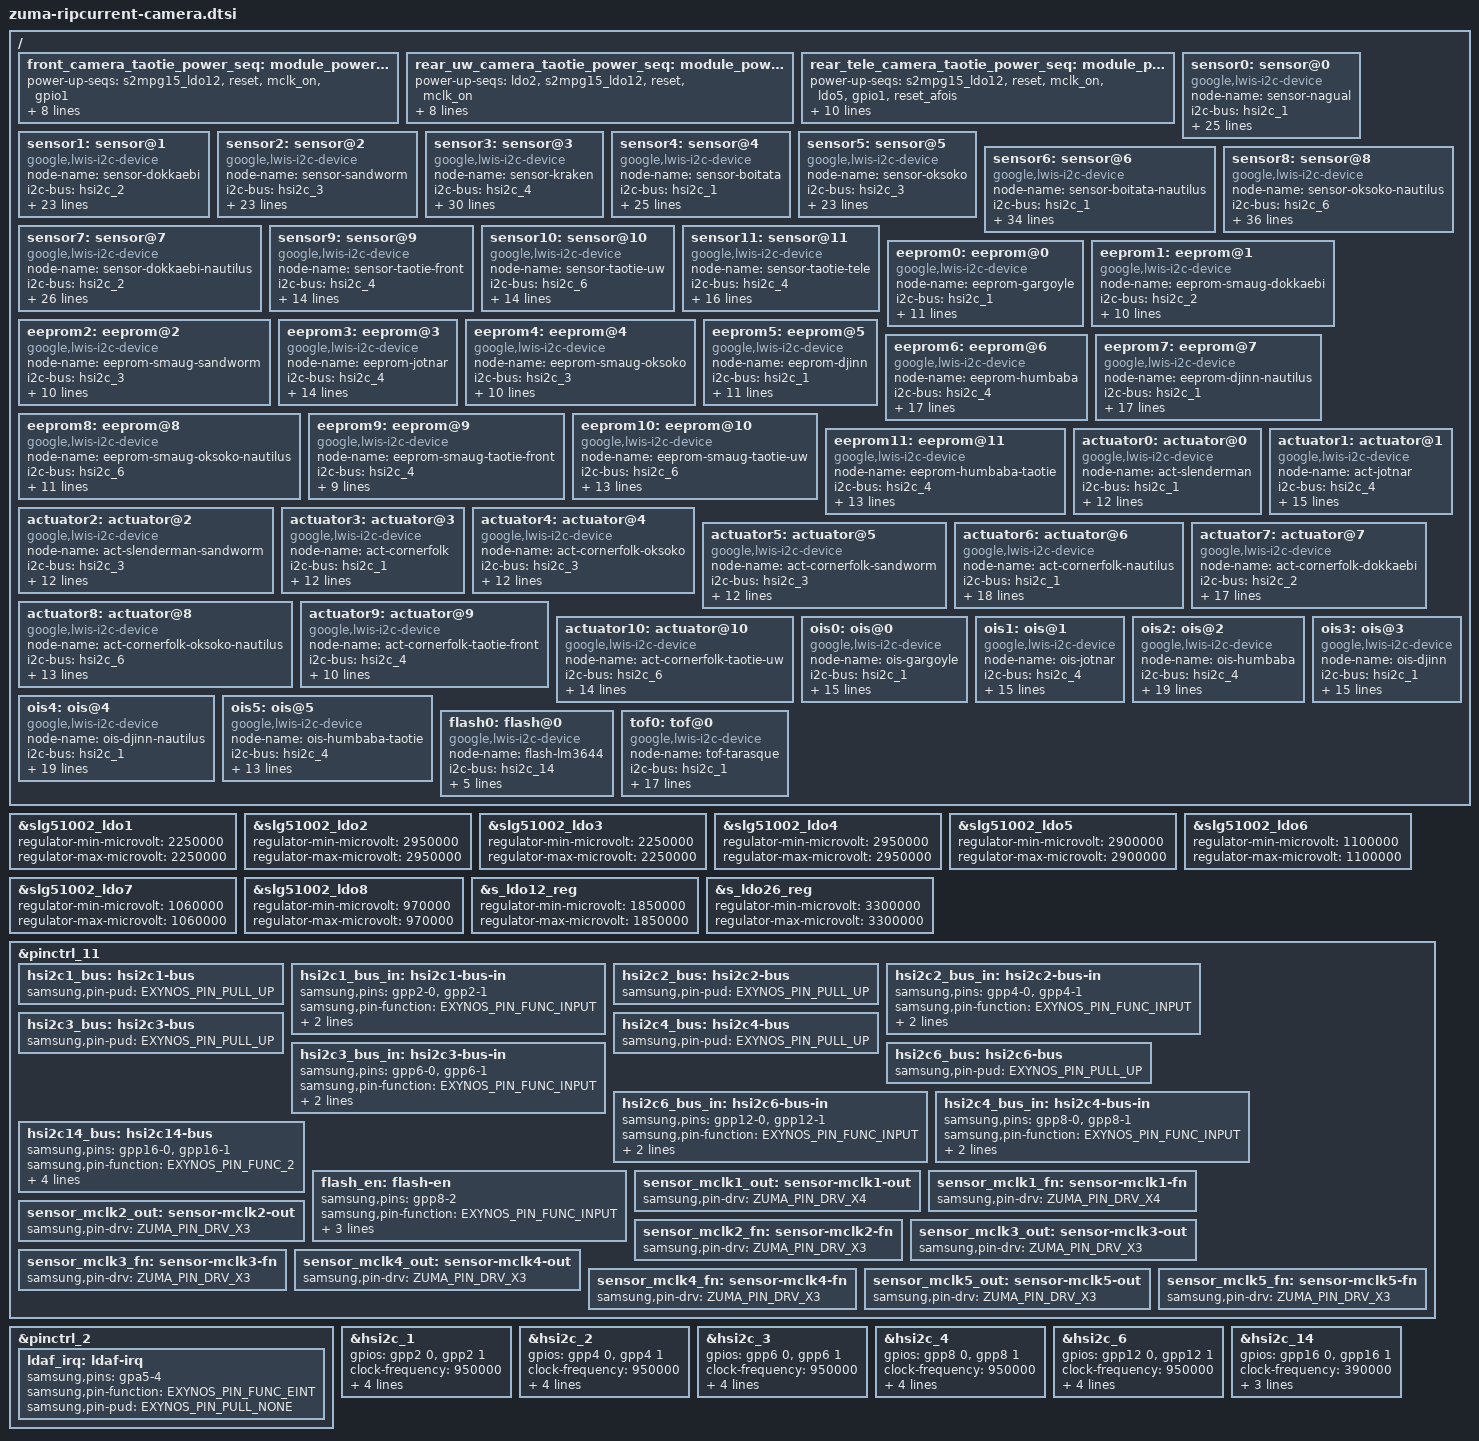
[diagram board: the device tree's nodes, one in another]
// SPDX-License-Identifier: GPL-2.0-only
/*
 * zuma camera lwis device tree for ripcurrent
 *
 * Copyright 2022 Google LLC.
 *
 */

#include <dt-bindings/clock/zuma.h>
#include <dt-bindings/gpio/gpio.h>
#include <arm64/exynos/exynos-pinctrl.h>
#include <dt-bindings/lwis/platform/zuma/tof.h>

&slg51002_ldo1 {
	regulator-min-microvolt = <2250000>;
	regulator-max-microvolt = <2250000>;
};

&slg51002_ldo2 {
	regulator-min-microvolt = <2950000>;
	regulator-max-microvolt = <2950000>;
};

&slg51002_ldo3 {
	regulator-min-microvolt = <2250000>;
	regulator-max-microvolt = <2250000>;
};

&slg51002_ldo4 {
	regulator-min-microvolt = <2950000>;
	regulator-max-microvolt = <2950000>;
};

&slg51002_ldo5 {
	regulator-min-microvolt = <2900000>;
	regulator-max-microvolt = <2900000>;
};

&slg51002_ldo6 {
	regulator-min-microvolt = <1100000>;
	regulator-max-microvolt = <1100000>;
};

&slg51002_ldo7 {
	regulator-min-microvolt = <1060000>;
	regulator-max-microvolt = <1060000>;
};

&slg51002_ldo8 {
	regulator-min-microvolt = <970000>;
	regulator-max-microvolt = <970000>;
};

&s_ldo12_reg {
	regulator-min-microvolt = <1850000>;
	regulator-max-microvolt = <1850000>;
};

&s_ldo26_reg {
	regulator-min-microvolt = <3300000>;
	regulator-max-microvolt = <3300000>;
};

&pinctrl_11 {
	hsi2c1_bus: hsi2c1-bus {
		samsung,pin-pud = <EXYNOS_PIN_PULL_UP>;
	};

	hsi2c1_bus_in: hsi2c1-bus-in {
		samsung,pins = "gpp2-0", "gpp2-1";
		samsung,pin-function = <EXYNOS_PIN_FUNC_INPUT>;
		samsung,pin-pud = <EXYNOS_PIN_PULL_NONE>;
		samsung,pin-drv = <ZUMA_PIN_DRV_X1>;
	};

	hsi2c2_bus: hsi2c2-bus {
		samsung,pin-pud = <EXYNOS_PIN_PULL_UP>;
	};

	hsi2c2_bus_in: hsi2c2-bus-in {
		samsung,pins = "gpp4-0", "gpp4-1";
		samsung,pin-function = <EXYNOS_PIN_FUNC_INPUT>;
		samsung,pin-pud = <EXYNOS_PIN_PULL_NONE>;
		samsung,pin-drv = <ZUMA_PIN_DRV_X1>;
	};

	hsi2c3_bus: hsi2c3-bus {
		samsung,pin-pud = <EXYNOS_PIN_PULL_UP>;
	};

	hsi2c3_bus_in: hsi2c3-bus-in {
		samsung,pins = "gpp6-0", "gpp6-1";
		samsung,pin-function = <EXYNOS_PIN_FUNC_INPUT>;
		samsung,pin-pud = <EXYNOS_PIN_PULL_NONE>;
		samsung,pin-drv = <ZUMA_PIN_DRV_X1>;
	};

	hsi2c4_bus: hsi2c4-bus {
		samsung,pin-pud = <EXYNOS_PIN_PULL_UP>;
	};

	hsi2c6_bus: hsi2c6-bus {
		samsung,pin-pud = <EXYNOS_PIN_PULL_UP>;
	};

	hsi2c6_bus_in: hsi2c6-bus-in {
		samsung,pins = "gpp12-0", "gpp12-1";
		samsung,pin-function = <EXYNOS_PIN_FUNC_INPUT>;
		samsung,pin-pud = <EXYNOS_PIN_PULL_NONE>;
		samsung,pin-drv = <ZUMA_PIN_DRV_X1>;
	};

	hsi2c4_bus_in: hsi2c4-bus-in {
		samsung,pins = "gpp8-0", "gpp8-1";
		samsung,pin-function = <EXYNOS_PIN_FUNC_INPUT>;
		samsung,pin-pud = <EXYNOS_PIN_PULL_NONE>;
		samsung,pin-drv = <ZUMA_PIN_DRV_X1>;
	};

	hsi2c14_bus: hsi2c14-bus {
		samsung,pins = "gpp16-0", "gpp16-1";
		samsung,pin-function = <EXYNOS_PIN_FUNC_2>;
		samsung,pin-pud = <EXYNOS_PIN_PULL_NONE>;
		samsung,pin-drv = <ZUMA_PIN_DRV_X1>;
		samsung,pin-con-pdn = <EXYNOS_PIN_PDN_PREV>;
		samsung,pin-pud-pdn = <EXYNOS_PIN_PULL_NONE>;
	};

	/* GPP8[2] Flashlight Enable */
	flash_en: flash-en {
		samsung,pins = "gpp8-2";
		samsung,pin-function = <EXYNOS_PIN_FUNC_INPUT>;
		samsung,pin-pud = <EXYNOS_PIN_PULL_NONE>;
		samsung,pin-con-pdn = <EXYNOS_PIN_PDN_PREV>;
		samsung,pin-pud-pdn = <EXYNOS_PIN_PULL_NONE>;
	};

	sensor_mclk1_out: sensor-mclk1-out {
		samsung,pin-drv = <ZUMA_PIN_DRV_X4>;
	};
	sensor_mclk1_fn: sensor-mclk1-fn {
		samsung,pin-drv = <ZUMA_PIN_DRV_X4>;
	};
	sensor_mclk2_out: sensor-mclk2-out {
		samsung,pin-drv = <ZUMA_PIN_DRV_X3>;
	};
	sensor_mclk2_fn: sensor-mclk2-fn {
		samsung,pin-drv = <ZUMA_PIN_DRV_X3>;
	};
	sensor_mclk3_out: sensor-mclk3-out {
		samsung,pin-drv = <ZUMA_PIN_DRV_X3>;
	};
	sensor_mclk3_fn: sensor-mclk3-fn {
		samsung,pin-drv = <ZUMA_PIN_DRV_X3>;
	};
	sensor_mclk4_out: sensor-mclk4-out {
		samsung,pin-drv = <ZUMA_PIN_DRV_X3>;
	};
	sensor_mclk4_fn: sensor-mclk4-fn {
		samsung,pin-drv = <ZUMA_PIN_DRV_X3>;
	};
	sensor_mclk5_out: sensor-mclk5-out {
		samsung,pin-drv = <ZUMA_PIN_DRV_X3>;
	};
	sensor_mclk5_fn: sensor-mclk5-fn {
		samsung,pin-drv = <ZUMA_PIN_DRV_X3>;
	};
};

&pinctrl_2 {
	ldaf_irq: ldaf-irq {
		samsung,pins = "gpa5-4"; /* XEINT_4 */
		samsung,pin-function = <EXYNOS_PIN_FUNC_EINT>;
		samsung,pin-pud = <EXYNOS_PIN_PULL_NONE>;
	};
};

&hsi2c_1 {
	#address-cells = <1>;
	#size-cells = <0>;
	gpios = <&gpp2 0 GPIO_ACTIVE_HIGH &gpp2 1 GPIO_ACTIVE_HIGH>;
	status = "okay";
	clock-frequency = <950000>;
	samsung,reset-before-trans;

	pinctrl-names = "default","on_i2c","off_i2c";
	pinctrl-0 = <&hsi2c1_bus_in>;
	pinctrl-1 = <&hsi2c1_bus>;
	pinctrl-2 = <&hsi2c1_bus_in>;
};

&hsi2c_2 {
	#address-cells = <1>;
	#size-cells = <0>;
	gpios = <&gpp4 0 GPIO_ACTIVE_HIGH &gpp4 1 GPIO_ACTIVE_HIGH>;
	status = "okay";
	clock-frequency = <950000>;
	samsung,reset-before-trans;

	pinctrl-names = "default","on_i2c","off_i2c";
	pinctrl-0 = <&hsi2c2_bus_in>;
	pinctrl-1 = <&hsi2c2_bus>;
	pinctrl-2 = <&hsi2c2_bus_in>;
};

&hsi2c_3 {
	#address-cells = <1>;
	#size-cells = <0>;
	gpios = <&gpp6 0 GPIO_ACTIVE_HIGH &gpp6 1 GPIO_ACTIVE_HIGH>;
	status = "okay";
	clock-frequency = <950000>;
	samsung,reset-before-trans;

	pinctrl-names = "default","on_i2c","off_i2c";
	pinctrl-0 = <&hsi2c3_bus_in>;
	pinctrl-1 = <&hsi2c3_bus>;
	pinctrl-2 = <&hsi2c3_bus_in>;
};

&hsi2c_4 {
	#address-cells = <1>;
	#size-cells = <0>;
	gpios = <&gpp8 0 GPIO_ACTIVE_HIGH &gpp8 1 GPIO_ACTIVE_HIGH>;
	status = "okay";
	clock-frequency = <950000>;
	samsung,reset-before-trans;

	pinctrl-names = "default","on_i2c","off_i2c";
	pinctrl-0 = <&hsi2c4_bus_in>;
	pinctrl-1 = <&hsi2c4_bus>;
	pinctrl-2 = <&hsi2c4_bus_in>;
};

&hsi2c_6 {
	#address-cells = <1>;
	#size-cells = <0>;
	gpios = <&gpp12 0 GPIO_ACTIVE_HIGH &gpp12 1 GPIO_ACTIVE_HIGH>;
	status = "okay";
	clock-frequency = <950000>;
	samsung,reset-before-trans;

	pinctrl-names = "default","on_i2c","off_i2c";
	pinctrl-0 = <&hsi2c6_bus_in>;
	pinctrl-1 = <&hsi2c6_bus>;
	pinctrl-2 = <&hsi2c6_bus_in>;
};

&hsi2c_14 {
	#address-cells = <1>;
	#size-cells = <0>;
	gpios = <&gpp16 0 GPIO_ACTIVE_HIGH &gpp16 1 GPIO_ACTIVE_HIGH>;
	status = "okay";
	clock-frequency = <390000>;

	pinctrl-names = "default","on_i2c","off_i2c";
	pinctrl-0 = <&hsi2c14_bus &flash_en>;
	pinctrl-1 = <&hsi2c14_bus>;
	pinctrl-2 = <&hsi2c14_bus>;
};
/ {
	fragment@lwiscamera {
		target-path = "/";
		__overlay__ {
			/* Power sequence for FRONT CAMERA TAOTIE combo */
			front_camera_taotie_power_seq: module_power_seq@0 {
				/* Power supplies will be defined on each module. */
				/* Power up sequence */
				power-up-seqs =
					/* Sensor power seq */
					/* VDIG(EN_BUCK_CAM) already up from PMIC */
					"s2mpg15_ldo12",
					"reset",
					"mclk_on",
					/* Actuator power seq */
					"gpio1";
				power-up-seq-types =
					"regulator",
					"gpio",
					"pinctrl",
					"regulator";
				power-up-seq-delays-us =
					<1000
					 0
					 /* >40k cycles (50k) on 24.57MHz clock (24MHz) */
					 /* 50k / 24MHz = around 2ms */
					 /* +1ms for additional delay */
					 3000
					 0>;

				/* Power down sequence */
				power-down-seqs =
					"gpio1",
					"mclk_off",
					"reset",
					"s2mpg15_ldo12";
				power-down-seq-types =
					"regulator",
					"pinctrl",
					"gpio",
					"regulator";
				power-down-seq-delays-us =
					<1000
					 0
					 0
					 0>;
			};

			/* Power sequence for REAR ULTRA WIDE TAOTIE combo */
			rear_uw_camera_taotie_power_seq: module_power_seq@1 {
				/* Power supplies will be defined on each module. */
				/* Power up sequence */
				power-up-seqs =
					/* Sensor power seq */
					/* VDIG,VIO(EN_BUCK_CAM) already up from PMIC */
					"ldo2",
					/* Actuator also up by i2c power pin*/
					"s2mpg15_ldo12",
					"reset",
					"mclk_on";

				power-up-seq-types =
					"regulator",
					"regulator",
					"gpio",
					"pinctrl";
				power-up-seq-delays-us =
					<1000
					 0
					 0
					 /* >40k cycles (50k) on 24.57MHz clock (24MHz) */
					 /* 50k / 24MHz = around 2ms */
					 /* +1ms for additional delay */
					 3000>;

				/* Power down sequence */
				power-down-seqs =
					"mclk_off",
					"reset",
					"s2mpg15_ldo12",
					"ldo2";
				power-down-seq-types =
					"pinctrl",
					"gpio",
					"regulator",
					"regulator";
				power-down-seq-delays-us =
					<0
					 1000
					 0
					 0>;
			};

			/* Power sequence for REAR Folded Tele Camera TAOTIE combo */
			rear_tele_camera_taotie_power_seq: module_power_seq@2 {
				/* Power supplies will be defined on each module. */
				/* Power up sequence */
				power-up-seqs =
					/* Sensor power seq */
					/* VDIG(EN_BUCK_CAM) already up from PMIC */
					"s2mpg15_ldo12",
					"reset",
					"mclk_on",
					/* AFOIS power seq */
					/* VDDIO already up by i2c power */
					"ldo5",
					"gpio1",
					"reset_afois";
				power-up-seq-types =
					"regulator",
					"gpio",
					"pinctrl",
					"regulator",
					"regulator",
					"gpio";
				power-up-seq-delays-us =
					<1000
					 0
					 /* >40k cycles (50k) on 24.57MHz clock (24MHz) */
					 /* 50k / 24MHz = around 2ms */
					 /* +1ms for additional delay */
					 3000
					 1000
					 1000
					 0>;

				/* Power down sequence */
				power-down-seqs =
					"reset_afois",
					"gpio1",
					"ldo5",
					"mclk_off",
					"reset",
					"s2mpg15_ldo12";
				power-down-seq-types =
					"gpio",
					"regulator",
					"regulator",
					"pinctrl",
					"gpio",
					"regulator";
				power-down-seq-delays-us =
					<1000
					 1000
					 1000
					 1000
					 0
					 0>;
			};

			/* REAR CAMERA NAGUAL */
			sensor0: sensor@0 {
				compatible = "google,lwis-i2c-device";

				/* Device node name */
				node-name = "sensor-nagual";

				/* I2C */
				i2c-bus = <&hsi2c_1>;
				i2c-addr = <0x3D>;

				/* Registers */
				reg-addr-bitwidth = <16>;
				reg-value-bitwidth = <16>;

				/* GPIOs */
				/* RCAM_RST_L GPP2[2] */
				reset-gpios = <&gpp2 2 GPIO_ACTIVE_HIGH>;

				/* Power supplies */
				s2mpg15_ldo12-supply = <&s_ldo12_reg>;
				ldo1-supply = <&slg51002_ldo1>;
				ldo8-supply = <&slg51002_ldo8>;
				gpio3-supply = <&slg51002_gpio3>;

				clocks =
					<&clock CIS_CLK3>,
					<&clock GATE_DFTMUX_CMU_CIS_CLK3>;
				clock-names =
					"CIS_CLK3",
					"GATE_DFTMUX_CMU_CIS_CLK3";
				clock-rates =
					<26000000>,
					<0>;

				/* MCLK Control */
				pinctrl-names = "mclk_on", "mclk_off";
				pinctrl-0 = <&sensor_mclk4_fn>;
				pinctrl-1 = <&sensor_mclk4_out>;

				/* Power up sequence */
				power-up-seqs =
					"s2mpg15_ldo12",
					"gpio3",
					"ldo8",
					"ldo1",
					"reset",
					"mclk_on";
				power-up-seq-types =
					"regulator",
					"regulator",
					"regulator",
					"regulator",
					"gpio",
					"pinctrl";
				power-up-seq-delays-us =
					<1000
					 0
					 0
					 2000
					 1000
					 9000>;

				/* Power down sequence */
				power-down-seqs =
					"mclk_off",
					"reset",
					"ldo1",
					"ldo8",
					"gpio3",
					"s2mpg15_ldo12";
				power-down-seq-types =
					"pinctrl",
					"gpio",
					"regulator",
					"regulator",
					"regulator",
					"regulator";
				power-down-seq-delays-us =
					<1000
					 1000
					 0
					 0
					 6000
					 0>;

				/* Thread priority */
				transaction-thread-priority = <99>;
			};

			/* FRONT CAMERA DOKKAEBI */
			sensor1: sensor@1 {
				compatible = "google,lwis-i2c-device";

				/* Device node name */
				node-name = "sensor-dokkaebi";

				/* I2C */
				i2c-bus = <&hsi2c_2>;
				i2c-addr = <0x10>;

				/* Registers */
				reg-addr-bitwidth = <16>;
				reg-value-bitwidth = <16>;

				/* GPIOs */
				reset-gpios = <&gpp4 2 GPIO_ACTIVE_HIGH>;

				/* Power supplies */
				s2mpg15_ldo12-supply = <&s_ldo12_reg>;
				ldo8-supply = <&slg51002_ldo8>;
				gpio4-supply = <&slg51002_gpio4>;

				clocks =
					<&clock CIS_CLK1>,
					<&clock GATE_DFTMUX_CMU_CIS_CLK1>;
				clock-names =
					"CIS_CLK1",
					"GATE_DFTMUX_CMU_CIS_CLK1";
				clock-rates =
					<24000000>,
					<0>;

				/* MCLK Control */
				pinctrl-names = "mclk_on", "mclk_off";
				pinctrl-0 = <&sensor_mclk2_fn>;
				pinctrl-1 = <&sensor_mclk2_out>;

				/* Power up sequence */
				power-up-seqs =
					"s2mpg15_ldo12",
					"ldo8",
					"gpio4",
					"mclk_on",
					"reset";
				power-up-seq-types =
					"regulator",
					"regulator",
					"regulator",
					"pinctrl",
					"gpio";
				power-up-seq-delays-us =
					<0
					 0
					 1000
					 1000
					 8000>;

				/* Power down sequence */
				power-down-seqs =
					"reset",
					"mclk_off",
					"gpio4",
					"ldo8",
					"s2mpg15_ldo12";
				power-down-seq-types =
					"gpio",
					"pinctrl",
					"regulator",
					"regulator",
					"regulator";
				power-down-seq-delays-us =
					<0
					 1000
					 0
					 0
					 1000>;

				/* Thread priority */
				transaction-thread-priority = <99>;
			};

			/* REAR ULTRA WIDE CAMERA SANDWORM */
			sensor2: sensor@2 {
				compatible = "google,lwis-i2c-device";

				/* Device node name */
				node-name = "sensor-sandworm";

				/* I2C */
				i2c-bus = <&hsi2c_3>;
				i2c-addr = <0x1A>;

				/* Registers */
				reg-addr-bitwidth = <16>;
				reg-value-bitwidth = <8>;

				/* GPIOs */
				reset-gpios = <&gpp6 3 GPIO_ACTIVE_HIGH>;

				/* Power supplies */
				s2mpg15_ldo12-supply = <&s_ldo12_reg>;
				ldo2-supply = <&slg51002_ldo2>;
				ldo6-supply = <&slg51002_ldo6>;

				clocks =
					<&clock CIS_CLK0>,
					<&clock GATE_DFTMUX_CMU_CIS_CLK0>;
				clock-names =
					"CIS_CLK0",
					"GATE_DFTMUX_CMU_CIS_CLK0";
				clock-rates =
					<24000000>,
					<0>;

				/* MCLK Control */
				pinctrl-names = "mclk_on", "mclk_off";
				pinctrl-0 = <&sensor_mclk1_fn>;
				pinctrl-1 = <&sensor_mclk1_out>;

				/* Power up sequence */
				power-up-seqs =
					"s2mpg15_ldo12",
					"ldo6",
					"ldo2",
					"mclk_on",
					"reset";
				power-up-seq-types =
					"regulator",
					"regulator",
					"regulator",
					"pinctrl",
					"gpio";
				power-up-seq-delays-us =
					<0
					 0
					 1000
					 1000
					 10000>;

				/* Power down sequence */
				power-down-seqs =
					"reset",
					"mclk_off",
					"ldo2",
					"ldo6",
					"s2mpg15_ldo12";
				power-down-seq-types =
					"gpio",
					"pinctrl",
					"regulator",
					"regulator",
					"regulator";
				power-down-seq-delays-us =
					<1000
					 1000
					 0
					 0
					 1000>;

				/* Thread priority */
				transaction-thread-priority = <99>;
			};

			/* REAR Folded Tele Camera KRAKEN */
			sensor3: sensor@3 {
				compatible = "google,lwis-i2c-device";

				/* Device node name */
				node-name = "sensor-kraken";

				/* I2C */
				i2c-bus = <&hsi2c_4>;
				i2c-addr = <0x2D>;

				/* Registers */
				reg-addr-bitwidth = <16>;
				reg-value-bitwidth = <16>;

				/* GPIOs */
				/* RTCAM_RST_L GPP6[2] */
				reset-gpios = <&gpp6 2 GPIO_ACTIVE_HIGH>;

				/* Power supplies */
				s2mpg15_ldo12-supply = <&s_ldo12_reg>;
				ldo3-supply = <&slg51002_ldo3>;
				ldo5-supply = <&slg51002_ldo5>;
				ldo7-supply = <&slg51002_ldo7>;
				gpio2-supply = <&slg51002_gpio2>;
				gpio4-supply = <&slg51002_gpio4>;

				clocks =
					<&clock CIS_CLK2>,
					<&clock GATE_DFTMUX_CMU_CIS_CLK2>;
				clock-names =
					"CIS_CLK2",
					"GATE_DFTMUX_CMU_CIS_CLK2";
				clock-rates =
					<24000000>,
					<0>;

				/* MCLK Control */
				pinctrl-names = "mclk_on", "mclk_off";
				pinctrl-0 = <&sensor_mclk3_fn>;
				pinctrl-1 = <&sensor_mclk3_out>;

				/* Power up sequence */
				power-up-seqs =
					"s2mpg15_ldo12",
					"ldo7",
					"ldo3",
					"ldo5",
					"gpio4",
					"mclk_on",
					"reset";
				power-up-seq-types =
					"regulator",
					"regulator",
					"regulator",
					"regulator",
					"regulator",
					"pinctrl",
					"gpio";
				power-up-seq-delays-us =
					<300
					 0
					 0
					 500
					 500
					 1000
					 10000>;

				/* Power down sequence */
				power-down-seqs =
					"reset",
					"mclk_off",
					"gpio4",
					"ldo5",
					"ldo7",
					"s2mpg15_ldo12",
					"ldo3";
				power-down-seq-types =
					"gpio",
					"pinctrl",
					"regulator",
					"regulator",
					"regulator",
					"regulator",
					"regulator";
				power-down-seq-delays-us =
					<0
					 0
					 1000
					 0
					 0
					 0
					 0>;

				/* Thread priority */
				transaction-thread-priority = <99>;

				i2c-lock-group-id = <3>;
			};

			/* REAR CAMERA BOITATA */
			sensor4: sensor@4 {
				compatible = "google,lwis-i2c-device";

				/* Device node name */
				node-name = "sensor-boitata";

				/* I2C */
				i2c-bus = <&hsi2c_1>;
				i2c-addr = <0x3D>;

				/* Registers */
				reg-addr-bitwidth = <16>;
				reg-value-bitwidth = <16>;

				/* GPIOs */
				/* RCAM_RST_L GPP2[2] */
				reset-gpios = <&gpp2 2 GPIO_ACTIVE_HIGH>;

				/* Power supplies */
				s2mpg15_ldo12-supply = <&s_ldo12_reg>;
				ldo1-supply = <&slg51002_ldo1>;
				ldo8-supply = <&slg51002_ldo8>;
				gpio3-supply = <&slg51002_gpio3>;

				clocks =
					<&clock CIS_CLK3>,
					<&clock GATE_DFTMUX_CMU_CIS_CLK3>;
				clock-names =
					"CIS_CLK3",
					"GATE_DFTMUX_CMU_CIS_CLK3";
				clock-rates =
					<26000000>,
					<0>;

				/* MCLK Control */
				pinctrl-names = "mclk_on", "mclk_off";
				pinctrl-0 = <&sensor_mclk4_fn>;
				pinctrl-1 = <&sensor_mclk4_out>;

				/* Power up sequence */
				power-up-seqs =
					"s2mpg15_ldo12",
					"gpio3",
					"ldo8",
					"ldo1",
					"reset",
					"mclk_on";
				power-up-seq-types =
					"regulator",
					"regulator",
					"regulator",
					"regulator",
					"gpio",
					"pinctrl";
				power-up-seq-delays-us =
					<1000
					 0
					 0
					 2000
					 1000
					 9000>;

				/* Power down sequence */
				power-down-seqs =
					"mclk_off",
					"reset",
					"ldo1",
					"ldo8",
					"gpio3",
					"s2mpg15_ldo12";
				power-down-seq-types =
					"pinctrl",
					"gpio",
					"regulator",
					"regulator",
					"regulator",
					"regulator";
				power-down-seq-delays-us =
					<1000
					 1000
					 0
					 0
					 6000
					 0>;

				/* Thread priority */
				transaction-thread-priority = <99>;
			};

			/* REAR ULTRA WIDE CAMERA OKSOKO */
			sensor5: sensor@5 {
				compatible = "google,lwis-i2c-device";

				/* Device node name */
				node-name = "sensor-oksoko";

				/* I2C */
				i2c-bus = <&hsi2c_3>;
				i2c-addr = <0x1A>;

				/* Registers */
				reg-addr-bitwidth = <16>;
				reg-value-bitwidth = <8>;

				/* GPIOs */
				reset-gpios = <&gpp6 3 GPIO_ACTIVE_HIGH>;

				/* Power supplies */
				s2mpg15_ldo12-supply = <&s_ldo12_reg>;
				ldo2-supply = <&slg51002_ldo2>;
				ldo6-supply = <&slg51002_ldo6>;

				clocks =
					<&clock CIS_CLK0>,
					<&clock GATE_DFTMUX_CMU_CIS_CLK0>;
				clock-names =
					"CIS_CLK0",
					"GATE_DFTMUX_CMU_CIS_CLK0";
				clock-rates =
					<24000000>,
					<0>;

				/* MCLK Control */
				pinctrl-names = "mclk_on", "mclk_off";
				pinctrl-0 = <&sensor_mclk1_fn>;
				pinctrl-1 = <&sensor_mclk1_out>;

				/* Power up sequence */
				power-up-seqs =
					"s2mpg15_ldo12",
					"ldo6",
					"ldo2",
					"mclk_on",
					"reset";
				power-up-seq-types =
					"regulator",
					"regulator",
					"regulator",
					"pinctrl",
					"gpio";
				power-up-seq-delays-us =
					<0
					 0
					 1000
					 1000
					 10000>;

				/* Power down sequence */
				power-down-seqs =
					"reset",
					"mclk_off",
					"ldo2",
					"ldo6",
					"s2mpg15_ldo12";
				power-down-seq-types =
					"gpio",
					"pinctrl",
					"regulator",
					"regulator",
					"regulator";
				power-down-seq-delays-us =
					<1000
					 1000
					 0
					 0
					 1000>;

				/* Thread priority */
				transaction-thread-priority = <99>;
			};

			/* REAR CAMERA BOITATA Nautilus */
			sensor6: sensor@6 {
				compatible = "google,lwis-i2c-device";

				/* Device node name */
				node-name = "sensor-boitata-nautilus";

				/* I2C */
				i2c-bus = <&hsi2c_1>;
				i2c-addr = <0x3D>;

				/* Registers */
				reg-addr-bitwidth = <16>;
				reg-value-bitwidth = <16>;
				/* CAMS_LVBUCK_EN for ldo8 */
				enable-gpios = <&s2mpg15_gpio 2 GPIO_ACTIVE_HIGH>;

				/* GPIOs */
				/* RCAM_RST_L GPP2[2] */
				reset-gpios = <&gpp2 2 GPIO_ACTIVE_HIGH>;

				/* Power supplies */
				s2mpg15_ldo26-supply = <&s_ldo26_reg>;
				s2mpg15_ldo12-supply = <&s_ldo12_reg>;
				ldo1-supply = <&slg51002_ldo1>;
				ldo8-supply = <&slg51002_ldo8>;
				ldo4-supply = <&slg51002_ldo4>;
				gpio2-supply = <&slg51002_gpio2>;

				clocks =
					<&clock CIS_CLK3>,
					<&clock GATE_DFTMUX_CMU_CIS_CLK3>;
				clock-names =
					"CIS_CLK3",
					"GATE_DFTMUX_CMU_CIS_CLK3";
				clock-rates =
					<26000000>,
					<0>;

				/* MCLK Control */
				pinctrl-names = "mclk_on", "mclk_off";
				pinctrl-0 = <&sensor_mclk4_fn>;
				pinctrl-1 = <&sensor_mclk4_out>;

				/* Power up sequence */
				power-up-seqs =
					"ldo1",
					"enable",
					"gpio2",
					"ldo8",
					"s2mpg15_ldo26",
					"s2mpg15_ldo12",
					"ldo4",
					"reset",
					"mclk_on";
				power-up-seq-types =
					"regulator",
					"gpio",
					"regulator",
					"regulator",
					"regulator",
					"regulator",
					"regulator",
					"gpio",
					"pinctrl";
				power-up-seq-delays-us =
					<500
					 500
					 500
					 0
					 0
					 0
					 2000
					 1000
					 9000>;

				/* Power down sequence */
				power-down-seqs =
					"mclk_off",
					"reset",
					"ldo4",
					"s2mpg15_ldo12",
					"s2mpg15_ldo26",
					"ldo8",
					"enable",
					"gpio2",
					"ldo1";
				power-down-seq-types =
					"pinctrl",
					"gpio",
					"regulator",
					"regulator",
					"regulator",
					"regulator",
					"gpio",
					"regulator",
					"regulator";
				power-down-seq-delays-us =
					<1000
					 1000
					 0
					 0
					 0
					 0
					 0
					 0
					 0>;

				/* Thread priority */
				transaction-thread-priority = <99>;

				i2c-lock-group-id = <0>;
			};

			/* FRONT CAMERA DOKKAEBI Nautilus */
			sensor7: sensor@7 {
				compatible = "google,lwis-i2c-device";

				/* Device node name */
				node-name = "sensor-dokkaebi-nautilus";

				/* I2C */
				i2c-bus = <&hsi2c_2>;
				i2c-addr = <0x10>;

				/* Registers */
				reg-addr-bitwidth = <16>;
				reg-value-bitwidth = <16>;

				/* GPIOs */
				reset-gpios = <&gpp4 2 GPIO_ACTIVE_HIGH>;
				/* Include front AF power sequence in front cam */
				shared-enable-gpios = <&s2mpg15_gpio 4 GPIO_ACTIVE_HIGH>;

				/* Power supplies */
				s2mpg15_ldo26-supply = <&s_ldo26_reg>;
				s2mpg15_ldo12-supply = <&s_ldo12_reg>;
				gpio3-supply = <&slg51002_gpio3>;

				clocks =
					<&clock CIS_CLK1>,
					<&clock GATE_DFTMUX_CMU_CIS_CLK1>;
				clock-names =
					"CIS_CLK1",
					"GATE_DFTMUX_CMU_CIS_CLK1";
				clock-rates =
					<24000000>,
					<0>;

				/* MCLK Control */
				pinctrl-names = "mclk_on", "mclk_off";
				pinctrl-0 = <&sensor_mclk2_fn>;
				pinctrl-1 = <&sensor_mclk2_out>;

				/* Power up sequence */
				power-up-seqs =
					"s2mpg15_ldo26",
					"s2mpg15_ldo12",
					"gpio3",
					"shared-enable",
					"mclk_on",
					"reset";
				power-up-seq-types =
					"regulator",
					"regulator",
					"regulator",
					"gpio",
					"pinctrl",
					"gpio";
				power-up-seq-delays-us =
					<0
					 0
					 500
					 500
					 1000
					 8000>;

				/* Power down sequence */
				power-down-seqs =
					"reset",
					"shared-enable",
					"mclk_off",
					"gpio3",
					"s2mpg15_ldo12",
					"s2mpg15_ldo26";
				power-down-seq-types =
					"gpio",
					"gpio",
					"pinctrl",
					"regulator",
					"regulator",
					"regulator";
				power-down-seq-delays-us =
					<0
					 0
					 1000
					 0
					 0
					 1000>;

				/* Thread priority */
				transaction-thread-priority = <99>;

				i2c-lock-group-id = <1>;
			};


			/* REAR ULTRA WIDE CAMERA OKSOKO Nautilus */
			sensor8: sensor@8 {
				compatible = "google,lwis-i2c-device";

				/* Device node name */
				node-name = "sensor-oksoko-nautilus";

				/* I2C */
				i2c-bus = <&hsi2c_6>;
				i2c-addr = <0x1A>;

				/* Registers */
				reg-addr-bitwidth = <16>;
				reg-value-bitwidth = <8>;

				/* GPIOs */
				reset-gpios = <&gpp2 3 GPIO_ACTIVE_HIGH>;

				/* Power supplies */
				s2mpg15_ldo12-supply = <&s_ldo12_reg>;
				ldo2-supply = <&slg51002_ldo2>;
				ldo4-supply = <&slg51002_ldo4>;
				ldo6-supply = <&slg51002_ldo6>;
				gpio2-supply = <&slg51002_gpio2>;

				clocks =
					<&clock CIS_CLK4>,
					<&clock GATE_DFTMUX_CMU_CIS_CLK4>;
				clock-names =
					"CIS_CLK4",
					"GATE_DFTMUX_CMU_CIS_CLK4";
				clock-rates =
					<24000000>,
					<0>;

				/* MCLK Control */
				pinctrl-names = "mclk_on", "mclk_off";
				pinctrl-0 = <&sensor_mclk5_fn>;
				pinctrl-1 = <&sensor_mclk5_out>;

				/* Power up sequence */
				power-up-seqs =
					"s2mpg15_ldo12",
					"ldo6",
					"ldo2",
					"ldo4",
					"gpio2",
					"mclk_on",
					"reset";
				power-up-seq-types =
					"regulator",
					"regulator",
					"regulator",
					"regulator",
					"regulator",
					"pinctrl",
					"gpio";
				power-up-seq-delays-us =
					<0
					 0
					 0
					 0
					 1000
					 1000
					 10000>;

				/* Power down sequence */
				power-down-seqs =
					"reset",
					"mclk_off",
					"gpio2",
					"ldo4",
					"ldo2",
					"ldo6",
					"s2mpg15_ldo12";
				power-down-seq-types =
					"gpio",
					"pinctrl",
					"regulator",
					"regulator",
					"regulator",
					"regulator",
					"regulator";
				power-down-seq-delays-us =
					<1000
					 1000
					 0
					 0
					 0
					 0
					 1000>;

				/* resume sequence */
				resume-seqs = "reset";
				resume-seq-types = "gpio";
				resume-seq-delays-us = <7600>;

				/* suspend sequence */
				suspend-seqs = "reset";
				suspend-seq-types = "gpio";
				suspend-seq-delays-us = <0>;

				/* Thread priority */
				transaction-thread-priority = <99>;

				i2c-lock-group-id = <2>;
			};

			/* FRONT CAMERA TAOTIE */
			sensor9: sensor@9 {
				compatible = "google,lwis-i2c-device";

				/* Device node name */
				node-name = "sensor-taotie-front";

				/* I2C */
				i2c-bus = <&hsi2c_4>;
				i2c-addr = <0x1A>;

				/* Registers */
				reg-addr-bitwidth = <16>;
				reg-value-bitwidth = <8>;

				/* GPIOs */
				/* RTCAM_RST_L GPP6[2] */
				reset-gpios = <&gpp6 2 GPIO_ACTIVE_HIGH>;
				/* EN_BUCK_CAM already up from PMIC */

				/* Power supplies */
				s2mpg15_ldo12-supply = <&s_ldo12_reg>;
				gpio1-supply = <&slg51002_gpio1>;

				clocks =
					<&clock CIS_CLK2>,
					<&clock GATE_DFTMUX_CMU_CIS_CLK2>;
				clock-names =
					"CIS_CLK2",
					"GATE_DFTMUX_CMU_CIS_CLK2";
				clock-rates =
					<24000000>,
					<0>;

				/* MCLK Control */
				pinctrl-names = "mclk_on", "mclk_off";
				pinctrl-0 = <&sensor_mclk3_fn>;
				pinctrl-1 = <&sensor_mclk3_out>;

				/* Power sequence */
				power-seq = <&front_camera_taotie_power_seq>;

				/* Thread priority */
				transaction-thread-priority = <99>;

				i2c-lock-group-id = <3>;
			};

			/* REAR ULTRA WIDE CAMERA TAOTIE */
			sensor10: sensor@10 {
				compatible = "google,lwis-i2c-device";

				/* Device node name */
				node-name = "sensor-taotie-uw";

				/* I2C */
				i2c-bus = <&hsi2c_6>;
				i2c-addr = <0x1A>;

				/* Registers */
				reg-addr-bitwidth = <16>;
				reg-value-bitwidth = <8>;

				/* GPIOs */
				reset-gpios = <&gpp2 3 GPIO_ACTIVE_HIGH>;
				/* EN_BUCK_CAM already up from PMIC */

				/* Power supplies */
				s2mpg15_ldo12-supply = <&s_ldo12_reg>;
				ldo2-supply = <&slg51002_ldo2>;

				clocks =
					<&clock CIS_CLK4>,
					<&clock GATE_DFTMUX_CMU_CIS_CLK4>;
				clock-names =
					"CIS_CLK4",
					"GATE_DFTMUX_CMU_CIS_CLK4";
				clock-rates =
					<24000000>,
					<0>;

				/* MCLK Control */
				pinctrl-names = "mclk_on", "mclk_off";
				pinctrl-0 = <&sensor_mclk5_fn>;
				pinctrl-1 = <&sensor_mclk5_out>;

				/* Power sequence */
				power-seq = <&rear_uw_camera_taotie_power_seq>;

				/* Thread priority */
				transaction-thread-priority = <99>;

				i2c-lock-group-id = <2>;
			};

			/* REAR Folded Tele Camera TAOTIE */
			sensor11: sensor@11 {
				compatible = "google,lwis-i2c-device";

				/* Device node name */
				node-name = "sensor-taotie-tele";

				/* I2C */
				i2c-bus = <&hsi2c_4>;
				i2c-addr = <0x33>;

				/* Registers */
				reg-addr-bitwidth = <16>;
				reg-value-bitwidth = <8>;

				/* GPIOs */
				/* RTCAM_RST_L GPP6[2] */
				reset-gpios = <&gpp6 2 GPIO_ACTIVE_HIGH>;
				reset_afois-gpios = <&gpp24 2 GPIO_ACTIVE_HIGH>;
				/* EN_BUCK_CAM already up from PMIC */

				/* Power supplies */
				s2mpg15_ldo12-supply = <&s_ldo12_reg>;
				ldo5-supply = <&slg51002_ldo5>;
				gpio1-supply = <&slg51002_gpio1>;

				clocks =
					<&clock CIS_CLK2>,
					<&clock GATE_DFTMUX_CMU_CIS_CLK2>;
				clock-names =
					"CIS_CLK2",
					"GATE_DFTMUX_CMU_CIS_CLK2";
				clock-rates =
					<24000000>,
					<0>;

				/* MCLK Control */
				pinctrl-names = "mclk_on", "mclk_off";
				pinctrl-0 = <&sensor_mclk3_fn>;
				pinctrl-1 = <&sensor_mclk3_out>;

				/* Power sequence */
				power-seq = <&rear_tele_camera_taotie_power_seq>;

				/* Thread priority */
				transaction-thread-priority = <99>;

				i2c-lock-group-id = <3>;
			};

			/* EEPROM GARGOYLE for NAGUAL*/
			eeprom0: eeprom@0 {
				compatible = "google,lwis-i2c-device";

				/* Device node name */
				node-name = "eeprom-gargoyle";

				/* I2C */
				i2c-bus = <&hsi2c_1>;
				i2c-addr = <0x24>;

				/* Registers */
				reg-addr-bitwidth = <16>;
				reg-value-bitwidth = <32>;

				/* Power supplies */
				s2mpg15_ldo12-supply = <&s_ldo12_reg>;
				gpio1-supply = <&slg51002_gpio1>;

				/* Power up sequence */
				power-up-seqs =
					"s2mpg15_ldo12",
					"gpio1";
				power-up-seq-types =
					"regulator",
					"regulator";
				power-up-seq-delays-us =
					<1000
					 1000>;

				/* Power down sequence */
				power-down-seqs =
					"gpio1",
					"s2mpg15_ldo12";
				power-down-seq-types =
					"regulator",
					"regulator";
				power-down-seq-delays-us =
					<1000
					 1000>;
			};

			/* EEPROM SMAUG for DOKKAEBI */
			eeprom1: eeprom@1 {
				compatible = "google,lwis-i2c-device";

				/* Device node name */
				node-name = "eeprom-smaug-dokkaebi";

				/* I2C */
				i2c-bus = <&hsi2c_2>;
				i2c-addr = <0x51>;

				/* Registers */
				reg-addr-bitwidth = <16>;
				reg-value-bitwidth = <8>;

				/* Power supplies */
				s2mpg15_ldo12-supply = <&s_ldo12_reg>;

				/* Power up sequence */
				power-up-seqs =
					"s2mpg15_ldo12";
				power-up-seq-types =
					"regulator";
				power-up-seq-delays-us =
					<1000>;

				/* Power down sequence */
				power-down-seqs =
					"s2mpg15_ldo12";
				power-down-seq-types =
					"regulator";
				power-down-seq-delays-us =
					<1000>;
			};

			/* EEPROM SMAUG for SANDWORM */
			eeprom2: eeprom@2 {
				compatible = "google,lwis-i2c-device";

				/* Device node name */
				node-name = "eeprom-smaug-sandworm";

				/* I2C */
				i2c-bus = <&hsi2c_3>;
				i2c-addr = <0x50>;

				/* Registers */
				reg-addr-bitwidth = <16>;
				reg-value-bitwidth = <8>;

				/* Power supplies */
				s2mpg15_ldo12-supply = <&s_ldo12_reg>;

				/* Power up sequence */
				power-up-seqs =
					"s2mpg15_ldo12";
				power-up-seq-types =
					"regulator";
				power-up-seq-delays-us =
					<1000>;

				/* Power down sequence */
				power-down-seqs =
					"s2mpg15_ldo12";
				power-down-seq-types =
					"regulator";
				power-down-seq-delays-us =
					<1000>;
			};

			/* EEPROM JOTNAR for KRAKEN*/
			eeprom3: eeprom@3 {
				compatible = "google,lwis-i2c-device";

				/* Device node name */
				node-name = "eeprom-jotnar";

				/* I2C */
				i2c-bus = <&hsi2c_4>;
				i2c-addr = <0x34>;

				/* Registers */
				reg-addr-bitwidth = <16>;
				reg-value-bitwidth = <8>;

				/* Power supplies */
				s2mpg15_ldo12-supply = <&s_ldo12_reg>;
				ldo5-supply = <&slg51002_ldo5>;
				gpio1-supply = <&slg51002_gpio1>;

				/* Power up sequence */
				power-up-seqs =
					"s2mpg15_ldo12",
					"ldo5",
					"gpio1";
				power-up-seq-types =
					"regulator",
					"regulator",
					"regulator";
				power-up-seq-delays-us =
					<1000
					 0
					 0>;

				/* Power down sequence */
				power-down-seqs =
					"gpio1",
					"ldo5",
					"s2mpg15_ldo12";
				power-down-seq-types =
					"regulator",
					"regulator",
					"regulator";
				power-down-seq-delays-us =
					<0
					 0
					 0>;
			};

			/* EEPROM SMAUG for OKSOKO */
			eeprom4: eeprom@4 {
				compatible = "google,lwis-i2c-device";

				/* Device node name */
				node-name = "eeprom-smaug-oksoko";

				/* I2C */
				i2c-bus = <&hsi2c_3>;
				i2c-addr = <0x50>;

				/* Registers */
				reg-addr-bitwidth = <16>;
				reg-value-bitwidth = <8>;

				/* Power supplies */
				s2mpg15_ldo12-supply = <&s_ldo12_reg>;

				/* Power up sequence */
				power-up-seqs =
					"s2mpg15_ldo12";
				power-up-seq-types =
					"regulator";
				power-up-seq-delays-us =
					<1000>;

				/* Power down sequence */
				power-down-seqs =
					"s2mpg15_ldo12";
				power-down-seq-types =
					"regulator";
				power-down-seq-delays-us =
					<1000>;
			};

			/* EEPROM DJINN for BOITATA*/
			eeprom5: eeprom@5 {
				compatible = "google,lwis-i2c-device";

				/* Device node name */
				node-name = "eeprom-djinn";

				/* I2C */
				i2c-bus = <&hsi2c_1>;
				i2c-addr = <0x24>;

				/* Registers */
				reg-addr-bitwidth = <16>;
				reg-value-bitwidth = <32>;

				/* Power supplies */
				s2mpg15_ldo12-supply = <&s_ldo12_reg>;
				gpio1-supply = <&slg51002_gpio1>;

				/* Power up sequence */
				power-up-seqs =
					"s2mpg15_ldo12",
					"gpio1";
				power-up-seq-types =
					"regulator",
					"regulator";
				power-up-seq-delays-us =
					<1000
					 1000>;

				/* Power down sequence */
				power-down-seqs =
					"gpio1",
					"s2mpg15_ldo12";
				power-down-seq-types =
					"regulator",
					"regulator";
				power-down-seq-delays-us =
					<1000
					 1000>;
			};

			/* EEPROM HUMBABA for KRAKEN */
			eeprom6: eeprom@6 {
				compatible = "google,lwis-i2c-device";

				/* Device node name */
				node-name = "eeprom-humbaba";

				/* I2C */
				i2c-bus = <&hsi2c_4>;
				i2c-addr = <0x61>;

				/* Registers */
				reg-addr-bitwidth = <16>;
				reg-value-bitwidth = <8>;

				/* GPIOs */
				reset-gpios = <&gpp24 2 GPIO_ACTIVE_HIGH>;

				/* Power supplies */
				s2mpg15_ldo12-supply = <&s_ldo12_reg>;
				ldo5-supply = <&slg51002_ldo5>;
				gpio1-supply = <&slg51002_gpio1>;

				/* Power up sequence */
				power-up-seqs =
					"s2mpg15_ldo12",
					"ldo5",
					"gpio1",
					"reset";
				power-up-seq-types =
					"regulator",
					"regulator",
					"regulator",
					"gpio";
				power-up-seq-delays-us =
					<1000
					 1000
					 1000
					 0>;

				/* Power down sequence */
				power-down-seqs =
					"reset",
					"gpio1",
					"ldo5",
					"s2mpg15_ldo12";
				power-down-seq-types =
					"gpio",
					"regulator",
					"regulator",
					"regulator";
				power-down-seq-delays-us =
					<1000
					 1000
					 1000
					 0>;
			};

			/* EEPROM DJINN for BOITATA Nautilus */
			eeprom7: eeprom@7 {
				compatible = "google,lwis-i2c-device";
				/* Device node name */
				node-name = "eeprom-djinn-nautilus";
				/* I2C */
				i2c-bus = <&hsi2c_1>;
				i2c-addr = <0x24>;
				/* Registers */
				reg-addr-bitwidth = <16>;
				reg-value-bitwidth = <32>;
				/* Power supplies */
				s2mpg15_ldo26-supply = <&s_ldo26_reg>;
				s2mpg15_ldo12-supply = <&s_ldo12_reg>;
				ldo5-supply = <&slg51002_ldo5>;
				/* Power up sequence */
				power-up-seqs =
					"s2mpg15_ldo26",
					"s2mpg15_ldo12",
					"ldo5";
				power-up-seq-types =
					"regulator",
					"regulator",
					"regulator";
				power-up-seq-delays-us =
					<0
					 1000
					 1000>;
				/* Power down sequence */
				power-down-seqs =
					"ldo5",
					"s2mpg15_ldo12",
					"s2mpg15_ldo26";
				power-down-seq-types =
					"regulator",
					"regulator",
					"regulator";
				power-down-seq-delays-us =
					<1000
					 0
					 1000>;

				i2c-lock-group-id = <0>;
			};

			/* EEPROM SMAUG for OKSOKO Nautilus */
			eeprom8: eeprom@8 {
				compatible = "google,lwis-i2c-device";

				/* Device node name */
				node-name = "eeprom-smaug-oksoko-nautilus";

				/* I2C */
				i2c-bus = <&hsi2c_6>;
				i2c-addr = <0x50>;

				/* Registers */
				reg-addr-bitwidth = <16>;
				reg-value-bitwidth = <8>;

				/* Power supplies */
				s2mpg15_ldo12-supply = <&s_ldo12_reg>;

				/* Power up sequence */
				power-up-seqs =
					"s2mpg15_ldo12";
				power-up-seq-types =
					"regulator";
				power-up-seq-delays-us =
					<1000>;

				/* Power down sequence */
				power-down-seqs =
					"s2mpg15_ldo12";
				power-down-seq-types =
					"regulator";
				power-down-seq-delays-us =
					<1000>;

				i2c-lock-group-id = <2>;
			};

			/* EEPROM SMAUG for Front TAOTIE (Nautilus) */
			eeprom9: eeprom@9 {
				compatible = "google,lwis-i2c-device";

				/* Device node name */
				node-name = "eeprom-smaug-taotie-front";

				/* I2C */
				i2c-bus = <&hsi2c_4>;
				i2c-addr = <0x51>;

				/* Registers */
				reg-addr-bitwidth = <16>;
				reg-value-bitwidth = <8>;

				/* GPIOs */
				/* RTCAM_RST_L GPP6[2] */
				reset-gpios = <&gpp6 2 GPIO_ACTIVE_HIGH>;
				/* EN_BUCK_CAM already up from PMIC */

				/* Power supplies */
				s2mpg15_ldo12-supply = <&s_ldo12_reg>;
				gpio1-supply = <&slg51002_gpio1>;

				/* MCLK Control */
				pinctrl-names = "mclk_on", "mclk_off";
				pinctrl-0 = <&sensor_mclk3_fn>;
				pinctrl-1 = <&sensor_mclk3_out>;

				/* Power sequence */
				power-seq = <&front_camera_taotie_power_seq>;
			};

			/* EEPROM SMAUG for OKSOKO Nautilus */
			eeprom10: eeprom@10 {
				compatible = "google,lwis-i2c-device";

				/* Device node name */
				node-name = "eeprom-smaug-taotie-uw";

				/* I2C */
				i2c-bus = <&hsi2c_6>;
				i2c-addr = <0x50>;

				/* Registers */
				reg-addr-bitwidth = <16>;
				reg-value-bitwidth = <8>;

				/* GPIOs */
				reset-gpios = <&gpp2 3 GPIO_ACTIVE_HIGH>;
				/* EN_BUCK_CAM already up from PMIC */

				/* Power supplies */
				s2mpg15_ldo12-supply = <&s_ldo12_reg>;
				ldo2-supply = <&slg51002_ldo2>;

				clocks =
					<&clock CIS_CLK4>,
					<&clock GATE_DFTMUX_CMU_CIS_CLK4>;
				clock-names =
					"CIS_CLK4",
					"GATE_DFTMUX_CMU_CIS_CLK4";
				clock-rates =
					<24000000>,
					<0>;

				/* MCLK Control */
				pinctrl-names = "mclk_on", "mclk_off";
				pinctrl-0 = <&sensor_mclk5_fn>;
				pinctrl-1 = <&sensor_mclk5_out>;

				/* Power sequence */
				power-seq = <&rear_uw_camera_taotie_power_seq>;

				i2c-lock-group-id = <2>;
			};

			/* EEPROM HUMBABA for Rear Folded Tele Camera TAOTIE */
			eeprom11: eeprom@11 {
				compatible = "google,lwis-i2c-device";

				/* Device node name */
				node-name = "eeprom-humbaba-taotie";

				/* I2C */
				i2c-bus = <&hsi2c_4>;
				i2c-addr = <0x61>;

				/* Registers */
				reg-addr-bitwidth = <16>;
				reg-value-bitwidth = <8>;

				/* GPIOs */
				/* RTCAM_RST_L GPP6[2] */
				reset-gpios = <&gpp6 2 GPIO_ACTIVE_HIGH>;
				reset_afois-gpios = <&gpp24 2 GPIO_ACTIVE_HIGH>;
				/* EN_BUCK_CAM already up from PMIC */

				/* Power supplies */
				s2mpg15_ldo12-supply = <&s_ldo12_reg>;
				ldo5-supply = <&slg51002_ldo5>;
				gpio1-supply = <&slg51002_gpio1>;

				/* MCLK Control */
				pinctrl-names = "mclk_on", "mclk_off";
				pinctrl-0 = <&sensor_mclk3_fn>;
				pinctrl-1 = <&sensor_mclk3_out>;

				/* Power sequence */
				power-seq = <&rear_tele_camera_taotie_power_seq>;

				/* Thread priority */
				transaction-thread-priority = <99>;

				i2c-lock-group-id = <3>;
			};

			/* Actuator SLENDERMAN for NAGUAL*/
			actuator0: actuator@0 {
				compatible = "google,lwis-i2c-device";

				/* Device node name */
				node-name = "act-slenderman";

				/* I2C */
				i2c-bus = <&hsi2c_1>;
				i2c-addr = <0xC>;

				/* Registers */
				reg-addr-bitwidth = <8>;
				reg-value-bitwidth = <8>;

				/* Power supplies */
				s2mpg15_ldo12-supply = <&s_ldo12_reg>;
				ldo4-supply = <&slg51002_ldo4>;

				/* Power up sequence */
				power-up-seqs =
					"s2mpg15_ldo12",
					"ldo4";
				power-up-seq-types =
					"regulator",
					"regulator";
				power-up-seq-delays-us =
					<0
					 0>;

				/* Power down sequence */
				power-down-seqs =
					"ldo4",
					"s2mpg15_ldo12";
				power-down-seq-types =
					"regulator",
					"regulator";
				power-down-seq-delays-us =
					<0
					 0>;

				/* Thread priority */
				transaction-thread-priority = <99>;
			};

			/* Actuator JOTNAR for KRAKEN */
			actuator1: actuator@1 {
				compatible = "google,lwis-i2c-device";

				/* Device node name */
				node-name = "act-jotnar";

				/* I2C */
				i2c-bus = <&hsi2c_4>;
				i2c-addr = <0x34>;

				/* Registers */
				reg-addr-bitwidth = <16>;
				reg-value-bitwidth = <8>;

				/* Power supplies */
				s2mpg15_ldo12-supply = <&s_ldo12_reg>;
				ldo5-supply = <&slg51002_ldo5>;
				gpio1-supply = <&slg51002_gpio1>;

				/* Power up sequence */
				power-up-seqs =
					"s2mpg15_ldo12",
					"ldo5",
					"gpio1";
				power-up-seq-types =
					"regulator",
					"regulator",
					"regulator";
				power-up-seq-delays-us =
					<1000
					 0
					 0>;

				/* Power down sequence */
				power-down-seqs =
					"gpio1",
					"ldo5",
					"s2mpg15_ldo12";
				power-down-seq-types =
					"regulator",
					"regulator",
					"regulator";
				power-down-seq-delays-us =
					<0
					 0
					 0>;

				/* Thread priority */
				transaction-thread-priority = <99>;
			};

			/* Actuator SLENDERMAN for SANDWORM*/
			actuator2: actuator@2 {
				compatible = "google,lwis-i2c-device";

				/* Device node name */
				node-name = "act-slenderman-sandworm";

				/* I2C */
				i2c-bus = <&hsi2c_3>;
				i2c-addr = <0xF>;

				/* Registers */
				reg-addr-bitwidth = <8>;
				reg-value-bitwidth = <8>;

				/* Power supplies */
				s2mpg15_ldo12-supply = <&s_ldo12_reg>;
				ldo4-supply = <&slg51002_ldo4>;

				/* Power up sequence */
				power-up-seqs =
					"s2mpg15_ldo12",
					"ldo4";
				power-up-seq-types =
					"regulator",
					"regulator";
				power-up-seq-delays-us =
					<0
					 0>;

				/* Power down sequence */
				power-down-seqs =
					"ldo4",
					"s2mpg15_ldo12";
				power-down-seq-types =
					"regulator",
					"regulator";
				power-down-seq-delays-us =
					<0
					 0>;

				/* Thread priority */
				transaction-thread-priority = <99>;
			};

			/* Actuator CORNERFOLK for BOITATA */
			actuator3: actuator@3 {
				compatible = "google,lwis-i2c-device";

				/* Device node name */
				node-name = "act-cornerfolk";

				/* I2C */
				i2c-bus = <&hsi2c_1>;
				i2c-addr = <0xC>;

				/* Registers */
				reg-addr-bitwidth = <8>;
				reg-value-bitwidth = <8>;

				/* Power supplies */
				s2mpg15_ldo12-supply = <&s_ldo12_reg>;
				ldo4-supply = <&slg51002_ldo4>;

				/* Power up sequence */
				power-up-seqs =
					"s2mpg15_ldo12",
					"ldo4";
				power-up-seq-types =
					"regulator",
					"regulator";
				power-up-seq-delays-us =
					<0
					 0>;

				/* Power down sequence */
				power-down-seqs =
					"ldo4",
					"s2mpg15_ldo12";
				power-down-seq-types =
					"regulator",
					"regulator";
				power-down-seq-delays-us =
					<0
					 0>;

				/* Thread priority */
				transaction-thread-priority = <99>;
			};

			/* Actuator CORNERFOLK for OKSOKO */
			actuator4: actuator@4 {
				compatible = "google,lwis-i2c-device";

				/* Device node name */
				node-name = "act-cornerfolk-oksoko";

				/* I2C */
				i2c-bus = <&hsi2c_3>;
				i2c-addr = <0xF>;

				/* Registers */
				reg-addr-bitwidth = <8>;
				reg-value-bitwidth = <8>;

				/* Power supplies */
				s2mpg15_ldo12-supply = <&s_ldo12_reg>;
				ldo4-supply = <&slg51002_ldo4>;

				/* Power up sequence */
				power-up-seqs =
					"s2mpg15_ldo12",
					"ldo4";
				power-up-seq-types =
					"regulator",
					"regulator";
				power-up-seq-delays-us =
					<0
					 0>;

				/* Power down sequence */
				power-down-seqs =
					"ldo4",
					"s2mpg15_ldo12";
				power-down-seq-types =
					"regulator",
					"regulator";
				power-down-seq-delays-us =
					<0
					 0>;

				/* Thread priority */
				transaction-thread-priority = <99>;
			};

			/* Actuator CORNERFOLK for SANDWORM */
			actuator5: actuator@5 {
				compatible = "google,lwis-i2c-device";

				/* Device node name */
				node-name = "act-cornerfolk-sandworm";

				/* I2C */
				i2c-bus = <&hsi2c_3>;
				i2c-addr = <0xF>;

				/* Registers */
				reg-addr-bitwidth = <8>;
				reg-value-bitwidth = <8>;

				/* Power supplies */
				s2mpg15_ldo12-supply = <&s_ldo12_reg>;
				ldo4-supply = <&slg51002_ldo4>;

				/* Power up sequence */
				power-up-seqs =
					"s2mpg15_ldo12",
					"ldo4";
				power-up-seq-types =
					"regulator",
					"regulator";
				power-up-seq-delays-us =
					<0
					 0>;

				/* Power down sequence */
				power-down-seqs =
					"ldo4",
					"s2mpg15_ldo12";
				power-down-seq-types =
					"regulator",
					"regulator";
				power-down-seq-delays-us =
					<0
					 0>;

				/* Thread priority */
				transaction-thread-priority = <99>;
			};

			/* Actuator CORNERFOLK for BOITATA Nautilus */
			actuator6: actuator@6 {
				compatible = "google,lwis-i2c-device";

				/* Device node name */
				node-name = "act-cornerfolk-nautilus";

				/* I2C */
				i2c-bus = <&hsi2c_1>;
				i2c-addr = <0xC>;

				/* Registers */
				reg-addr-bitwidth = <8>;
				reg-value-bitwidth = <8>;

				/* Power supplies */
				s2mpg15_ldo26-supply = <&s_ldo26_reg>;
				s2mpg15_ldo12-supply = <&s_ldo12_reg>;
				ldo4-supply = <&slg51002_ldo4>;

				/* Power up sequence */
				power-up-seqs =
					"s2mpg15_ldo26",
					"s2mpg15_ldo12",
					"ldo4";
				power-up-seq-types =
					"regulator",
					"regulator",
					"regulator";
				power-up-seq-delays-us =
					<0
					 0
					 0>;

				/* Power down sequence */
				power-down-seqs =
					"ldo4",
					"s2mpg15_ldo12",
					"s2mpg15_ldo26";
				power-down-seq-types =
					"regulator",
					"regulator",
					"regulator";
				power-down-seq-delays-us =
					<0
					 0
					 0>;

				/* Thread priority */
				transaction-thread-priority = <99>;

				i2c-lock-group-id = <0>;
			};

			/* Actuator CORNERFOLK for DOKKAEBI on Nautilus */
			actuator7: actuator@7 {
				compatible = "google,lwis-i2c-device";

				/* Device node name */
				node-name = "act-cornerfolk-dokkaebi";

				/* I2C */
				i2c-bus = <&hsi2c_2>;
				i2c-addr = <0xC>;

				/* Registers */
				reg-addr-bitwidth = <8>;
				reg-value-bitwidth = <8>;

				/* Power supplies */
				s2mpg15_ldo12-supply = <&s_ldo12_reg>;
				shared-enable-gpios = <&s2mpg15_gpio 4 GPIO_ACTIVE_HIGH>;
				/* Make front AF can be powered up alone */
				gpio3-supply = <&slg51002_gpio3>;


				/* Power up sequence */
				power-up-seqs =
					"s2mpg15_ldo12",
					"gpio3",
					"shared-enable";
				power-up-seq-types =
					"regulator",
					"regulator",
					"gpio";
				power-up-seq-delays-us =
					<1000
					 500
					 0>;

				/* Power down sequence */
				power-down-seqs =
					"shared-enable",
					"gpio3",
					"s2mpg15_ldo12";
				power-down-seq-types =
					"gpio",
					"regulator",
					"regulator";
				power-down-seq-delays-us =
					<0
					 0
					 0>;

				/* Thread priority */
				transaction-thread-priority = <99>;

				i2c-lock-group-id = <1>;
			};

			/* Actuator CORNERFOLK for OKSOKO Nautilus */
			actuator8: actuator@8 {
				compatible = "google,lwis-i2c-device";

				/* Device node name */
				node-name = "act-cornerfolk-oksoko-nautilus";

				/* I2C */
				i2c-bus = <&hsi2c_6>;
				i2c-addr = <0xF>;

				/* Registers */
				reg-addr-bitwidth = <8>;
				reg-value-bitwidth = <8>;

				/* Power supplies */
				s2mpg15_ldo12-supply = <&s_ldo12_reg>;
				ldo4-supply = <&slg51002_ldo4>;

				/* Power up sequence */
				power-up-seqs =
					"s2mpg15_ldo12",
					"ldo4";
				power-up-seq-types =
					"regulator",
					"regulator";
				power-up-seq-delays-us =
					<0
					 0>;

				/* Power down sequence */
				power-down-seqs =
					"ldo4",
					"s2mpg15_ldo12";
				power-down-seq-types =
					"regulator",
					"regulator";
				power-down-seq-delays-us =
					<0
					 0>;

				/* Thread priority */
				transaction-thread-priority = <99>;

				i2c-lock-group-id = <2>;
			};

			/* Actuator CORNERFOLK for TAOTIE front (Nautilus) */
			actuator9: actuator@9 {
				compatible = "google,lwis-i2c-device";

				/* Device node name */
				node-name = "act-cornerfolk-taotie-front";

				/* I2C */
				i2c-bus = <&hsi2c_4>;
				i2c-addr = <0xC>;

				/* Registers */
				reg-addr-bitwidth = <8>;
				reg-value-bitwidth = <8>;

				/* GPIOs */
				/* RTCAM_RST_L GPP6[2] */
				reset-gpios = <&gpp6 2 GPIO_ACTIVE_HIGH>;
				/* EN_BUCK_CAM already up from PMIC */

				/* Power supplies */
				s2mpg15_ldo12-supply = <&s_ldo12_reg>;
				gpio1-supply = <&slg51002_gpio1>;

				/* MCLK Control */
				pinctrl-names = "mclk_on", "mclk_off";
				pinctrl-0 = <&sensor_mclk3_fn>;
				pinctrl-1 = <&sensor_mclk3_out>;

				/* Power sequence */
				power-seq = <&front_camera_taotie_power_seq>;

				/* Thread priority */
				transaction-thread-priority = <99>;
			};

			/* Actuator CORNERFOLK for REAR ULTRA WIDE TAOTIE */
			actuator10: actuator@10 {
				compatible = "google,lwis-i2c-device";

				/* Device node name */
				node-name = "act-cornerfolk-taotie-uw";

				/* I2C */
				i2c-bus = <&hsi2c_6>;
				i2c-addr = <0xF>;

				/* Registers */
				reg-addr-bitwidth = <8>;
				reg-value-bitwidth = <8>;

				/* GPIOs */
				reset-gpios = <&gpp2 3 GPIO_ACTIVE_HIGH>;
				/* EN_BUCK_CAM already up from PMIC */

				/* Power supplies */
				s2mpg15_ldo12-supply = <&s_ldo12_reg>;
				ldo2-supply = <&slg51002_ldo2>;

				clocks =
					<&clock CIS_CLK4>,
					<&clock GATE_DFTMUX_CMU_CIS_CLK4>;
				clock-names =
					"CIS_CLK4",
					"GATE_DFTMUX_CMU_CIS_CLK4";
				clock-rates =
					<24000000>,
					<0>;

				/* MCLK Control */
				pinctrl-names = "mclk_on", "mclk_off";
				pinctrl-0 = <&sensor_mclk5_fn>;
				pinctrl-1 = <&sensor_mclk5_out>;

				/* Power sequence */
				power-seq = <&rear_uw_camera_taotie_power_seq>;

				/* Thread priority */
				transaction-thread-priority = <99>;

				i2c-lock-group-id = <2>;
			};

			/* Ois GARGOYLE for NAGUAL*/
			ois0: ois@0 {
				compatible = "google,lwis-i2c-device";

				/* Device node name */
				node-name = "ois-gargoyle";

				/* I2C */
				i2c-bus = <&hsi2c_1>;
				i2c-addr = <0x24>;

				/* Registers */
				reg-addr-bitwidth = <16>;
				reg-value-bitwidth = <32>;

				/* Power supplies */
				s2mpg15_ldo12-supply = <&s_ldo12_reg>;
				gpio1-supply = <&slg51002_gpio1>;
				gpio2-supply = <&slg51002_gpio2>;

				/* Power up sequence */
				power-up-seqs =
					"s2mpg15_ldo12",
					"gpio1",
					"gpio2";
				power-up-seq-types =
					"regulator",
					"regulator",
					"regulator";
				power-up-seq-delays-us =
					<1000
					 1000
					 1000>;

				/* Power down sequence */
				power-down-seqs =
					"gpio2",
					"gpio1",
					"s2mpg15_ldo12";
				power-down-seq-types =
					"regulator",
					"regulator",
					"regulator";
				power-down-seq-delays-us =
					<5000
					 4000
					 0>;

				/* Thread priority */
				transaction-thread-priority = <99>;
			};

			/* Ois JOTNAR for KRAKEN */
			ois1: ois@1 {
				compatible = "google,lwis-i2c-device";

				/* Device node name */
				node-name = "ois-jotnar";

				/* I2C */
				i2c-bus = <&hsi2c_4>;
				i2c-addr = <0x34>;

				/* Registers */
				reg-addr-bitwidth = <16>;
				reg-value-bitwidth = <8>;

				/* Power supplies */
				s2mpg15_ldo12-supply = <&s_ldo12_reg>;
				ldo5-supply = <&slg51002_ldo5>;
				gpio1-supply = <&slg51002_gpio1>;

				/* Power up sequence */
				power-up-seqs =
					"s2mpg15_ldo12",
					"ldo5",
					"gpio1";
				power-up-seq-types =
					"regulator",
					"regulator",
					"regulator";
				power-up-seq-delays-us =
					<1000
					 0
					 0>;

				/* Power down sequence */
				power-down-seqs =
					"gpio1",
					"ldo5",
					"s2mpg15_ldo12";
				power-down-seq-types =
					"regulator",
					"regulator",
					"regulator";
				power-down-seq-delays-us =
					<0
					 0
					 0>;

				/* Thread priority */
				transaction-thread-priority = <99>;
			};

			/* OIS HUMBABA for KRAKEN */
			ois2: ois@2 {
				compatible = "google,lwis-i2c-device";

				/* Device node name */
				node-name = "ois-humbaba";

				/* I2C */
				i2c-bus = <&hsi2c_4>;
				i2c-addr = <0x61>;

				/* Registers */
				reg-addr-bitwidth = <16>;
				reg-value-bitwidth = <8>;

				/* GPIOs */
				reset-gpios = <&gpp24 2 GPIO_ACTIVE_HIGH>;

				/* Power supplies */
				s2mpg15_ldo12-supply = <&s_ldo12_reg>;
				ldo5-supply = <&slg51002_ldo5>;
				gpio1-supply = <&slg51002_gpio1>;

				/* Power up sequence */
				power-up-seqs =
					"s2mpg15_ldo12",
					"ldo5",
					"gpio1",
					"reset";
				power-up-seq-types =
					"regulator",
					"regulator",
					"regulator",
					"gpio";
				power-up-seq-delays-us =
					<1000
					 1000
					 1000
					 0>;

				/* Power down sequence */
				power-down-seqs =
					"reset",
					"gpio1",
					"ldo5",
					"s2mpg15_ldo12";
				power-down-seq-types =
					"gpio",
					"regulator",
					"regulator",
					"regulator";
				power-down-seq-delays-us =
					<1000
					 1000
					 1000
					 0>;

				/* Thread priority */
				transaction-thread-priority = <99>;

				i2c-lock-group-id = <3>;
			};

			/* Ois DJINN for BOITATA*/
			ois3: ois@3 {
				compatible = "google,lwis-i2c-device";

				/* Device node name */
				node-name = "ois-djinn";

				/* I2C */
				i2c-bus = <&hsi2c_1>;
				i2c-addr = <0x24>;

				/* Registers */
				reg-addr-bitwidth = <16>;
				reg-value-bitwidth = <32>;

				/* Power supplies */
				s2mpg15_ldo12-supply = <&s_ldo12_reg>;
				gpio1-supply = <&slg51002_gpio1>;
				gpio2-supply = <&slg51002_gpio2>;

				/* Power up sequence */
				power-up-seqs =
					"s2mpg15_ldo12",
					"gpio1",
					"gpio2";
				power-up-seq-types =
					"regulator",
					"regulator",
					"regulator";
				power-up-seq-delays-us =
					<1000
					 1000
					 1000>;

				/* Power down sequence */
				power-down-seqs =
					"gpio2",
					"gpio1",
					"s2mpg15_ldo12";
				power-down-seq-types =
					"regulator",
					"regulator",
					"regulator";
				power-down-seq-delays-us =
					<5000
					 4000
					 0>;

				/* Thread priority */
				transaction-thread-priority = <99>;
			};

			/* OIS DJINN for BOITATA Nautilus */
			ois4: ois@4 {
				compatible = "google,lwis-i2c-device";

				/* Device node name */
				node-name = "ois-djinn-nautilus";

				/* I2C */
				i2c-bus = <&hsi2c_1>;
				i2c-addr = <0x24>;

				/* Registers */
				reg-addr-bitwidth = <16>;
				reg-value-bitwidth = <32>;

				/* Power supplies */
				s2mpg15_ldo26-supply = <&s_ldo26_reg>;
				s2mpg15_ldo12-supply = <&s_ldo12_reg>;
				ldo5-supply = <&slg51002_ldo5>;
				gpio4-supply = <&slg51002_gpio4>;

				/* Power up sequence */
				power-up-seqs =
					"s2mpg15_ldo26",
					"s2mpg15_ldo12",
					"ldo5",
					"gpio4";
				power-up-seq-types =
					"regulator",
					"regulator",
					"regulator",
					"regulator";
				power-up-seq-delays-us =
					< 0
					 1000
					 1000
					 1000>;

				/* Power down sequence */
				power-down-seqs =
					"gpio4",
					"ldo5",
					"s2mpg15_ldo12",
					"s2mpg15_ldo26";
				power-down-seq-types =
					"regulator",
					"regulator",
					"regulator",
					"regulator";
				power-down-seq-delays-us =
					<5000
					 4000
					 0
					 0>;

				/* Thread priority */
				transaction-thread-priority = <99>;

				i2c-lock-group-id = <0>;
			};

			/* OIS HUMBABA for Folded Tele Camera TAOTIE */
			ois5: ois@5 {
				compatible = "google,lwis-i2c-device";

				/* Device node name */
				node-name = "ois-humbaba-taotie";

				/* I2C */
				i2c-bus = <&hsi2c_4>;
				i2c-addr = <0x61>;

				/* Registers */
				reg-addr-bitwidth = <16>;
				reg-value-bitwidth = <8>;

				/* GPIOs */
				/* RTCAM_RST_L GPP6[2] */
				reset-gpios = <&gpp6 2 GPIO_ACTIVE_HIGH>;
				reset_afois-gpios = <&gpp24 2 GPIO_ACTIVE_HIGH>;
				/* EN_BUCK_CAM already up from PMIC */

				/* Power supplies */
				s2mpg15_ldo12-supply = <&s_ldo12_reg>;
				ldo5-supply = <&slg51002_ldo5>;
				gpio1-supply = <&slg51002_gpio1>;

				/* MCLK Control */
				pinctrl-names = "mclk_on", "mclk_off";
				pinctrl-0 = <&sensor_mclk3_fn>;
				pinctrl-1 = <&sensor_mclk3_out>;

				/* Power sequence */
				power-seq = <&rear_tele_camera_taotie_power_seq>;

				/* Thread priority */
				transaction-thread-priority = <99>;

				i2c-lock-group-id = <3>;
			};

			flash0: flash@0 {
				compatible = "google,lwis-i2c-device";

				/* Device node name */
				node-name = "flash-lm3644";

				/* I2C */
				i2c-bus = <&hsi2c_14>;
				i2c-addr = <0x63>;

				/* Registers */
				reg-addr-bitwidth = <8>;
				reg-value-bitwidth = <8>;

				/* Power Management hibernation (deep sleep) */
				/* 1 : enable, 0 : disable */
				pm-hibernation = <0>;

				/* GPIOs */
				/* HW_ENABLE GPP8[2] */
				enable-gpios =
					<&gpp8 2 GPIO_ACTIVE_HIGH>;
			};

			tof0: tof@0 {
				compatible = "google,lwis-i2c-device";

				/* Device node name */
				node-name = "tof-tarasque";

				/* I2C */
				i2c-bus = <&hsi2c_1>;
				i2c-addr = <0x29>;

				/* Registers */
				reg-addr-bitwidth = <16>;
				reg-value-bitwidth = <8>;

				/* Power supplies */
				s2mpg15_ldo12-supply = <&s_ldo12_reg>;
				ldo1-supply = <&slg51002_ldo1>;

				/* XAPC_USI4_CTSN_CSN: GPP8[3] */
				enable-gpios = <&gpp8 3 GPIO_ACTIVE_HIGH>;

				/* XAPC_MCLK8: GPP15[0] */
				reset-gpios = <&gpp15 0 GPIO_ACTIVE_HIGH>;

				/* Power up sequence */
				power-up-seqs =
					"s2mpg15_ldo12",
					"ldo1",
					"enable",
					"reset";
				power-up-seq-types =
					"regulator",
					"regulator",
					"gpio",
					"gpio";
				power-up-seq-delays-us =
					<1000
					 1000
					 1000
					 2000>;

				/* Power down sequence */
				power-down-seqs =
					"reset",
					"enable",
					"ldo1",
					"s2mpg15_ldo12";
				power-down-seq-types =
					"gpio",
					"gpio",
					"regulator",
					"regulator";
				power-down-seq-delays-us =
					<1000
					 1000
					 1000
					 1000>;
			};
		};
	};
};
